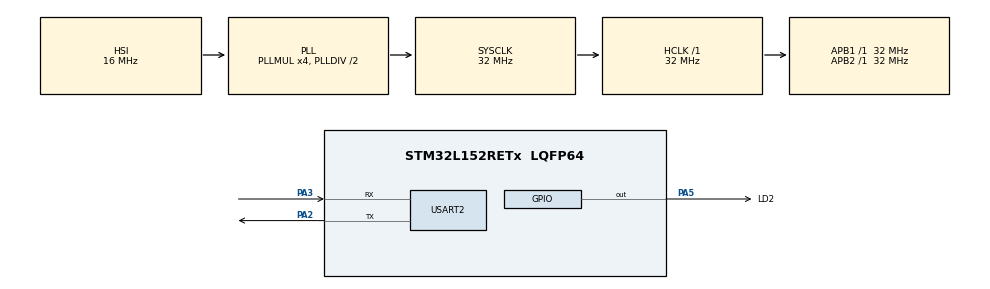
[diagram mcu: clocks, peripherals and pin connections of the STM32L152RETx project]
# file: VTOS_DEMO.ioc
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Dma.MEMTOMEM.0.Direction=DMA_MEMORY_TO_MEMORY
Dma.MEMTOMEM.0.Instance=DMA2_Channel1
Dma.MEMTOMEM.0.MemDataAlignment=DMA_MDATAALIGN_WORD
Dma.MEMTOMEM.0.MemInc=DMA_MINC_ENABLE
Dma.MEMTOMEM.0.Mode=DMA_NORMAL
Dma.MEMTOMEM.0.PeriphDataAlignment=DMA_PDATAALIGN_WORD
Dma.MEMTOMEM.0.PeriphInc=DMA_PINC_ENABLE
Dma.MEMTOMEM.0.Priority=DMA_PRIORITY_HIGH
Dma.MEMTOMEM.1.Direction=DMA_MEMORY_TO_MEMORY
Dma.MEMTOMEM.1.Instance=DMA1_Channel1
Dma.MEMTOMEM.1.MemDataAlignment=DMA_MDATAALIGN_BYTE
Dma.MEMTOMEM.1.MemInc=DMA_MINC_ENABLE
Dma.MEMTOMEM.1.Mode=DMA_NORMAL
Dma.MEMTOMEM.1.PeriphDataAlignment=DMA_PDATAALIGN_BYTE
Dma.MEMTOMEM.1.PeriphInc=DMA_PINC_ENABLE
Dma.MEMTOMEM.1.Priority=DMA_PRIORITY_HIGH
Dma.Request0=MEMTOMEM
Dma.Request1=MEMTOMEM
Mcu.Family=STM32L1
Mcu.Name=STM32L152RETx
Mcu.Package=LQFP64
NVIC.PriorityGroup=NVIC_PRIORITYGROUP_4
NVIC.TIM11_IRQn=true\:0\:0\:false\:false\:true
PA13.Mode=Serial_Wire
PA13.Signal=SYS_JTMS-SWDIO
PA14.Mode=Serial_Wire
PA14.Signal=SYS_JTCK-SWCLK
PA2.Mode=Multiprocessor_communication
PA2.Signal=USART2_TX
PA3.Mode=Multiprocessor_communication
PA3.Signal=USART2_RX
PA5.GPIO_Label=LD2
PA5.GPIO_PuPd=GPIO_PULLDOWN
PA5.GPIO_Speed=GPIO_SPEED_FREQ_VERY_HIGH
PA5.PinState=GPIO_PIN_RESET
PA5.Signal=GPIO_Output
PH0-OSC_IN.Mode=HSE-External-Oscillator
PH0-OSC_IN.Signal=RCC_OSC_IN
PH1-OSC_OUT.Mode=HSE-External-Oscillator
PH1-OSC_OUT.Signal=RCC_OSC_OUT
ProjectManager.HeapSize=0x8000
ProjectManager.StackSize=0x800
ProjectManager.TargetToolchain=MDK-ARM V5
RCC.AHBFreq_Value=32000000
RCC.APB1Freq_Value=32000000
RCC.APB1TimFreq_Value=32000000
RCC.APB2Freq_Value=32000000
RCC.APB2TimFreq_Value=32000000
RCC.HCLKFreq_Value=32000000
RCC.HSE_VALUE=24000000
RCC.HSI_VALUE=16000000
RCC.LSE_VALUE=32768
RCC.MSI_VALUE=2097000
RCC.PLLMUL=RCC_PLL_MUL4
RCC.SYSCLKFreq_VALUE=32000000
RCC.SYSCLKSource=RCC_SYSCLKSOURCE_PLLCLK
RCC.USBOutput=32000000
RCC.VCOOutputFreq_Value=64000000
TIM11.Period=19
TIM11.Prescaler=159
USART2.VirtualMode=VM_ASYNC
VP_TIM11_VS_ClockSourceINT.Mode=Internal
board=VTOS_DEMO

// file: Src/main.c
/**
  ******************************************************************************
  * File Name          : main.c
  * Description        : Main program body
  ******************************************************************************
  ** This notice applies to any and all portions of this file
  * that are not between comment pairs USER CODE BEGIN and
  * USER CODE END. Other portions of this file, whether
  * inserted by the user or by software development tools
  * are owned by their respective copyright owners.
  *
  * COPYRIGHT(c) 2017 STMicroelectronics
  *
  * Redistribution and use in source and binary forms, with or without modification,
  * are permitted provided that the following conditions are met:
  *   1. Redistributions of source code must retain the above copyright notice,
  *      this list of conditions and the following disclaimer.
  *   2. Redistributions in binary form must reproduce the above copyright notice,
  *      this list of conditions and the following disclaimer in the documentation
  *      and/or other materials provided with the distribution.
  *   3. Neither the name of STMicroelectronics nor the names of its contributors
  *      may be used to endorse or promote products derived from this software
  *      without specific prior written permission.
  *
  * THIS SOFTWARE IS PROVIDED BY THE COPYRIGHT HOLDERS AND CONTRIBUTORS "AS IS"
  * AND ANY EXPRESS OR IMPLIED WARRANTIES, INCLUDING, BUT NOT LIMITED TO, THE
  * IMPLIED WARRANTIES OF MERCHANTABILITY AND FITNESS FOR A PARTICULAR PURPOSE ARE
  * DISCLAIMED. IN NO EVENT SHALL THE COPYRIGHT HOLDER OR CONTRIBUTORS BE LIABLE
  * FOR ANY DIRECT, INDIRECT, INCIDENTAL, SPECIAL, EXEMPLARY, OR CONSEQUENTIAL
  * DAMAGES (INCLUDING, BUT NOT LIMITED TO, PROCUREMENT OF SUBSTITUTE GOODS OR
  * SERVICES; LOSS OF USE, DATA, OR PROFITS; OR BUSINESS INTERRUPTION) HOWEVER
  * CAUSED AND ON ANY THEORY OF LIABILITY, WHETHER IN CONTRACT, STRICT LIABILITY,
  * OR TORT (INCLUDING NEGLIGENCE OR OTHERWISE) ARISING IN ANY WAY OUT OF THE USE
  * OF THIS SOFTWARE, EVEN IF ADVISED OF THE POSSIBILITY OF SUCH DAMAGE.
  *
  ******************************************************************************
  */
#include "main.h"
#include "stm32l1xx_hal.h"
#include "dma.h"
#include "tim.h"
#include "usart.h"
#include "gpio.h"

/* USER CODE BEGIN Includes */
#include "vrtos.h"
#include "app_led.h"
/* USER CODE END Includes */

/* USER CODE BEGIN PV */
/* Private variables ---------------------------------------------------------*/

/* USER CODE END PV */

void SystemClock_Config(void);

/* USER CODE BEGIN PFP */
/* Private function prototypes -----------------------------------------------*/

/* USER CODE END PFP */

/* USER CODE BEGIN 0 */

static void app_task_register(void) {

}

void HAL_SYSTICK_Callback(void) {
    app_timer_timeouts_check();
}

void HAL_TIM_PeriodElapsedCallback(TIM_HandleTypeDef *htim) {
    if ( htim == &htim11 ) {
//        app_timer_timeouts_check();
    }
}
/* USER CODE END 0 */

int main(void)
{

  /* MCU Configuration----------------------------------------------------------*/

  /* Reset of all peripherals, Initializes the Flash interface and the Systick. */
  HAL_Init();

  /* Configure the system clock */
  SystemClock_Config();

  /* Initialize all configured peripherals */
  MX_GPIO_Init();
  MX_DMA_Init();
  MX_TIM11_Init();
  MX_USART2_UART_Init();

  /* USER CODE BEGIN 2 */
    app_task_init();
    app_timer_init();
    led_init();
    app_task_register();

    p_msg_handler_t new_msg = app_msg_create( LED_OP_TYPE_TURN_ON, NULL, 0 );
    app_msg_post_timer( 200, 0, APP_TIMER_MODE_SINGLE_SHOT, led_task_handler, new_msg );
    new_msg = app_msg_create( LED_OP_TYPE_TURN_OFF, NULL, 0);
    app_msg_post_timer( 400, 0, APP_TIMER_MODE_SINGLE_SHOT, led_task_handler, new_msg );

    app_timer_start();

    LOG("vtos start...system clock = %dHz\r\n", SystemCoreClock);
  /* USER CODE END 2 */

  /* Infinite loop */
    while (1)
    {

  /* USER CODE BEGIN 3 */
        task_dispatch();

    }
  /* USER CODE END 3 */

}

/** System Clock Configuration
*/
void SystemClock_Config(void)
{

  RCC_OscInitTypeDef RCC_OscInitStruct;
  RCC_ClkInitTypeDef RCC_ClkInitStruct;

    /**Configure the main internal regulator output voltage
    */
  __HAL_PWR_VOLTAGESCALING_CONFIG(PWR_REGULATOR_VOLTAGE_SCALE1);

    /**Initializes the CPU, AHB and APB busses clocks
    */
  RCC_OscInitStruct.OscillatorType = RCC_OSCILLATORTYPE_HSI;
  RCC_OscInitStruct.HSIState = RCC_HSI_ON;
  RCC_OscInitStruct.HSICalibrationValue = 16;
  RCC_OscInitStruct.PLL.PLLState = RCC_PLL_ON;
  RCC_OscInitStruct.PLL.PLLSource = RCC_PLLSOURCE_HSI;
  RCC_OscInitStruct.PLL.PLLMUL = RCC_PLL_MUL4;
  RCC_OscInitStruct.PLL.PLLDIV = RCC_PLL_DIV2;
  if (HAL_RCC_OscConfig(&RCC_OscInitStruct) != HAL_OK)
  {
    _Error_Handler(__FILE__, __LINE__);
  }

    /**Initializes the CPU, AHB and APB busses clocks
    */
  RCC_ClkInitStruct.ClockType = RCC_CLOCKTYPE_HCLK|RCC_CLOCKTYPE_SYSCLK
                              |RCC_CLOCKTYPE_PCLK1|RCC_CLOCKTYPE_PCLK2;
  RCC_ClkInitStruct.SYSCLKSource = RCC_SYSCLKSOURCE_PLLCLK;
  RCC_ClkInitStruct.AHBCLKDivider = RCC_SYSCLK_DIV1;
  RCC_ClkInitStruct.APB1CLKDivider = RCC_HCLK_DIV1;
  RCC_ClkInitStruct.APB2CLKDivider = RCC_HCLK_DIV1;

  if (HAL_RCC_ClockConfig(&RCC_ClkInitStruct, FLASH_LATENCY_1) != HAL_OK)
  {
    _Error_Handler(__FILE__, __LINE__);
  }

    /**Configure the Systick interrupt time
    */
  HAL_SYSTICK_Config(HAL_RCC_GetHCLKFreq()/1000);

    /**Configure the Systick
    */
  HAL_SYSTICK_CLKSourceConfig(SYSTICK_CLKSOURCE_HCLK);

  /* SysTick_IRQn interrupt configuration */
  HAL_NVIC_SetPriority(SysTick_IRQn, 0, 0);
}

void _Error_Handler(char * file, int line)
{
  while(1)
  {
  }
}

/************************ (C) COPYRIGHT STMicroelectronics *****END OF FILE****/
